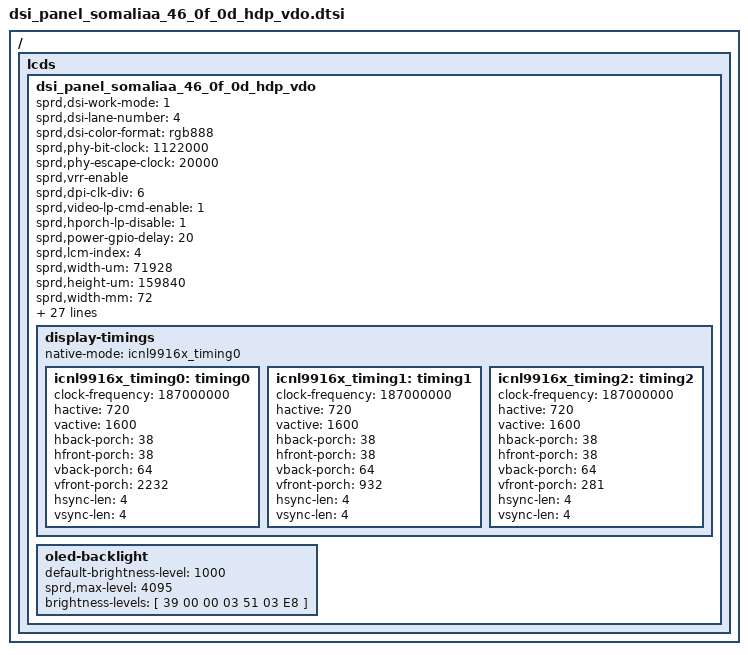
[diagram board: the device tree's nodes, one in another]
// SPDX-License-Identifier: GPL-2.0-only
/*
 * Unisoc HKC LCD config DTS file
 *
 * Copyright (C) 2021, Unisoc Inc.
 */
/ {
	fragment {
		target-path = "/";
		__overlay__ {
			lcds {
				dsi_panel_somaliaa_46_0f_0d_hdp_vdo: dsi_panel_somaliaa_46_0f_0d_hdp_vdo {
					sprd,dsi-work-mode = <1>; /* video burst mode*/
					sprd,dsi-lane-number = <4>;
					sprd,dsi-color-format = "rgb888";

					sprd,phy-bit-clock = <1122000>; /* kbps */
					sprd,phy-escape-clock = <20000>;/* kHz */
					sprd,vrr-enable;  /*120hz 90hz 60hz*/
					sprd,dpi-clk-div = <6>;
					sprd,video-lp-cmd-enable = <1>;
					sprd,hporch-lp-disable = <1>;
					sprd,power-gpio-delay = <20>;/* ms */

					sprd,lcm-index = <4>;/* panel Batch */
					sprd,width-um = <71928>;
					sprd,height-um = <159840>;
					sprd,width-mm = <72>;
					sprd,height-mm = <160>;
					sprd,esd-check-enable = <1>;
					sprd,esd-check-mode = <2>;
					sprd,esd-check-period = <3000>;
					// Unset params
					// sprd,esd-check-num = <1>;
					// sprd,esd-check-register = <0x0A>;
					// sprd,esd-check-value = <0x9C>;

					mi,bkl-normal-matrix = <8 2047 4095>;
					mi,bkl-remap-matrix = <11 3274 4095>;

					sprd,reset-on-sequence = <0 5>, <1 50>;
					sprd,reset-off-sequence = <1 5>;
					/*
					* Use 4 bits number for descripting video lp mode, and it can be combined used.
					* BIT(0): allow vactive enter lp;
					* BIT(1): allow vfp enter lp;
					* BIT(2): allow vbp enter lp;
					* BIT(3): allow vsa enter lp;
					* For example:
					* If we need vfp & vbp enter lp, we can calculate this value as a result of BIT(1) | BIT(2)
					* And we get the result of 3 and set this value to lcd dt property sprd,video-lp-en-mode.
					* If we need all stage can enter lp, we can calculate this value as a result of BIT(0) | BIT(1) | BIT(2) | BIT(3).
					* And we get the result of 15 and set this value to lcd dt property sprd,video-lp-en-mode.
					*/
					sprd,video-lp-en-mode = <11>;
					sprd,initial-command = [
						39 00 00 04 F0 99 16 18
						39 00 00 05 BD A1 2A 52 A6
						39 00 00 15 C1 01 40 19 04 30 30 04 40 06 22 40 31 01 07 1F FF 4C 00 E3 00

						39 00 00 03 C2 70 45

						39 00 00 21 E0 3A F0 3C 86 3C B8 3C F9 3D 3C 3D 72 3D B2 3E 35 3E A8 3F 30 3F 70 3F 90 3F 90 3F 90 3F 90 3F 90
						39 00 00 21 E1 2A 60 2D 3F 2E 3F 2F FF 31 47 32 8F 33 D6 35 1E 37 66 38 EF 3A 78 3C 01 3D 8A 3E B4 3F 28 3F 88
						39 00 00 21 E2 2D 80 30 5A 31 22 32 42 33 36 34 CF 36 66 37 CE 39 36 3A AA 3B 80 3C 71 3D 9A 3E B4 3F 28 3F 88
						39 00 00 21 E3 F1 F5 F7 F8 F9 FA FB FD FE FE FF FF FF FF FF FF EC EC EC EC EC EC ED EF F3 F5 F7 F9 FC FE FF FF
						39 00 00 21 E4 EF F0 F1 F2 F3 F4 F4 F5 F6 F8 FA FB FD FE FF FF 0F 1F 2F 3F 4F 5F 6F 7F 90 A0 B0 C0 D0 E0 F0 00
						39 00 00 21 E5 8C 00 10 00 00 00 00 00 00 0B 13 9F 00 B0 00 04 00 00 04 84 06 12 23 11 C7 00 00 00 00 00 00 00//PWM20K

						23 00 00 02 53 2C
						23 00 00 02 35 00
						39 00 00 03 51 00 00

						13 50 00 01 11
						13 14 00 01 29

						23 00 00 02 6D 02
						39 00 00 05 BD A1 2A 52 AE
						39 00 00 04 F0 00 00 00
					];

					sprd,sleep-in-command = [
						23 00 00 02 6D 25
						13 14 00 01 28
						13 78 00 01 10
					];

					sprd,sleep-out-command = [
						13 78 00 01 11
						13 0A 00 01 29
					];


					sprd,tp-proximity-command = [
						23 00 00 02 6D 25
						13 14 00 01 28
					];

					sprd,cabc-off-mode = [
						23 00 00 02 55 00
					];

					sprd,cabc-ui-mode = [
						23 00 00 02 55 01
					];

					sprd,cabc-mov-mode = [
						23 00 00 02 55 03
					];

					sprd,cabc-still-mode = [
						23 00 00 02 55 02
					];

					sprd,esd-cmd-page = [
						39 00 00 04 F0 99 16 18
					];

					sprd,main-cmd-page = [
						39 00 00 04 F0 00 00 00
					];

					sprd,cabc-bl-ctrl-on = [
						39 00 00 03 5E 00 0B
					];

					sprd,cabc-bl-ctrl-off = [
						39 00 00 03 5E 00 00
						23 00 00 02 53 24
					];

					display-timings {
						native-mode = <&icnl9916x_timing0>;

						icnl9916x_timing0: timing0 { //60hz
							clock-frequency = <187000000>;
							hactive = <720>;
							vactive = <1600>;
							hback-porch = <38>;
							hfront-porch = <38>;
							vback-porch = <64>;
							vfront-porch = <2232>;
							hsync-len = <4>;
							vsync-len = <4>;
						};

						icnl9916x_timing1: timing1 {  //90hz
							clock-frequency = <187000000>;
							hactive = <720>;
							vactive = <1600>;
							hback-porch = <38>;
							hfront-porch = <38>;
							vback-porch = <64>;
							vfront-porch = <932>;
							hsync-len = <4>;
							vsync-len = <4>;
						};

						icnl9916x_timing2: timing2 {  //120hz
							clock-frequency = <187000000>;
							hactive = <720>;
							vactive = <1600>;
							hback-porch = <38>;
							hfront-porch = <38>;
							vback-porch = <64>;
							vfront-porch = <281>;
							hsync-len = <4>;
							vsync-len = <4>;
						};
					};
					oled-backlight {
						default-brightness-level = <1000>;
						sprd,max-level = <4095>;
						brightness-levels = [
							39 00 00 03 51 03 E8
						];
					};
				};
			};
		};
	};
};
